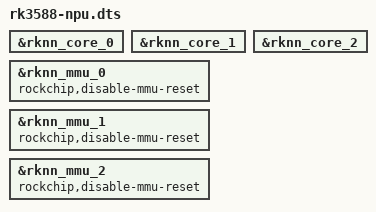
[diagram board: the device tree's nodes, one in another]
/dts-v1/;
/plugin/;

/* 
 * Enable the RK3588 NPU cores defined in mainline rk3588-base.dtsi.
 * This generic overlay is used by wharfmaster (Orange Pi 5) and assumes
 * power/regulators are handled by the base board DTS or default on.
 */

&rknn_core_0 {
    status = "okay";
};

&rknn_core_1 {
    status = "okay";
};

&rknn_core_2 {
    status = "okay";
};

&rknn_mmu_0 {
    status = "okay";
    rockchip,disable-mmu-reset;
};

&rknn_mmu_1 {
    status = "okay";
    rockchip,disable-mmu-reset;
};

&rknn_mmu_2 {
    status = "okay";
    rockchip,disable-mmu-reset;
};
